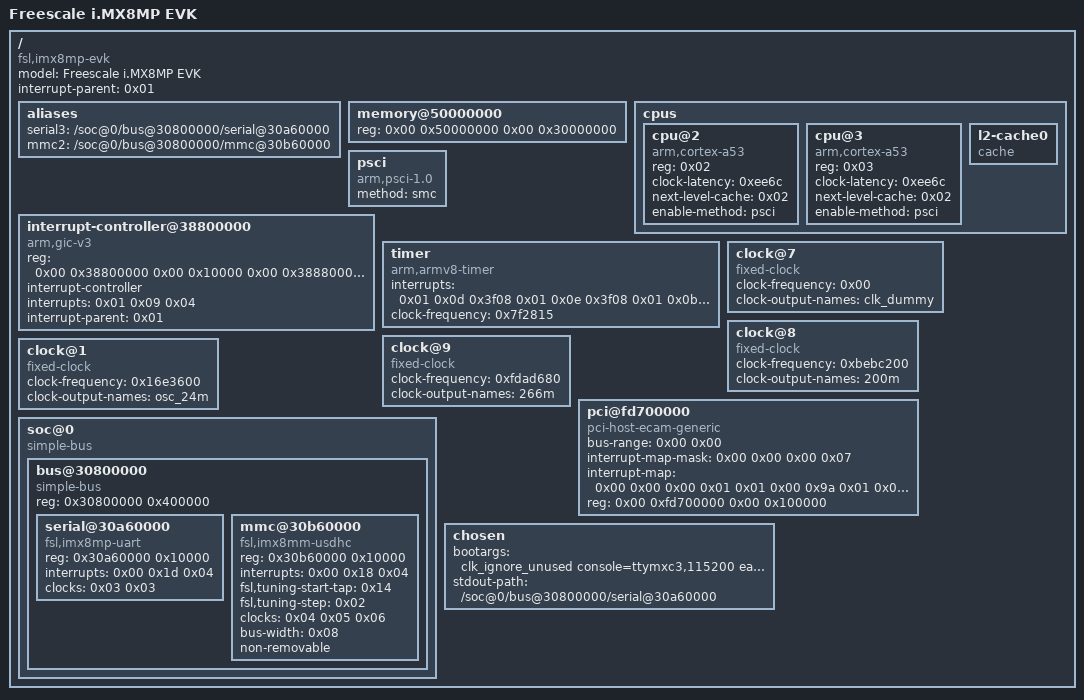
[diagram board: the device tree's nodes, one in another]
/dts-v1/;

/ {
	model = "Freescale i.MX8MP EVK";
	compatible = "fsl,imx8mp-evk\0fsl,imx8mp";
	interrupt-parent = <0x01>;
	#address-cells = <0x02>;
	#size-cells = <0x02>;

	aliases {
		serial3 = "/soc@0/bus@30800000/serial@30a60000";
		mmc2 = "/soc@0/bus@30800000/mmc@30b60000";
	};

	memory@50000000 {
		device_type = "memory";
		reg = <0x00 0x50000000 0x00 0x30000000>;
	};
	
	cpus {
		#address-cells = <0x01>;
		#size-cells = <0x00>;

		cpu@2 {
			device_type = "cpu";
			compatible = "arm,cortex-a53";
			reg = <0x02>;
			clock-latency = <0xee6c>;
			next-level-cache = <0x02>;
			enable-method = "psci";
			#cooling-cells = <0x02>;
		};

		cpu@3 {
			device_type = "cpu";
			compatible = "arm,cortex-a53";
			reg = <0x03>;
			clock-latency = <0xee6c>;
			next-level-cache = <0x02>;
			enable-method = "psci";
			#cooling-cells = <0x02>;
		};

		l2-cache0 {
			compatible = "cache";
			phandle = <0x02>;
		};
	};

	psci {
		compatible = "arm,psci-1.0";
		method = "smc";
	};

	interrupt-controller@38800000 {
		compatible = "arm,gic-v3";
		reg = <0x00 0x38800000 0x00 0x10000 0x00 0x38880000 0x00 0xc0000>;
		#interrupt-cells = <0x03>;
		interrupt-controller;
		interrupts = <0x01 0x09 0x04>;
		interrupt-parent = <0x01>;
		phandle = <0x01>;
	};

	timer {
		compatible = "arm,armv8-timer";
		interrupts = <0x01 0x0d 0x3f08 0x01 0x0e 0x3f08 0x01 0x0b 0x3f08 0x01 0x0a 0x3f08>;
		clock-frequency = <0x7f2815>;
	};

	clock@7 {
		compatible = "fixed-clock";
		#clock-cells = <0x00>;
		clock-frequency = <0x00>;
		clock-output-names = "clk_dummy";
		phandle = <0x04>;
	};

	clock@8 {
		compatible = "fixed-clock";
		#clock-cells = <0x00>;
		clock-frequency = <0xbebc200>;
		clock-output-names = "200m";
		phandle = <0x06>;
	};

	clock@9 {
		compatible = "fixed-clock";
		#clock-cells = <0x00>;
		clock-frequency = <0xfdad680>;
		clock-output-names = "266m";
		phandle = <0x05>;
	};

	clock@1 {
		compatible = "fixed-clock";
		#clock-cells = <0x00>;
		clock-frequency = <0x16e3600>;
		clock-output-names = "osc_24m";
		phandle = <0x03>;
	};

	pci@fd700000 {
		compatible = "pci-host-ecam-generic";
		device_type = "pci";
		bus-range = <0x00 0x00>;
		#address-cells = <0x03>;
		#size-cells = <0x02>;
		#interrupt-cells = <0x01>;
		interrupt-map-mask = <0x00 0x00 0x00 0x07>;
		interrupt-map = <0x00 0x00 0x00 0x01 0x01 0x00 0x9a 0x01 0x00 0x00 0x00 0x02 0x01 0x00 0x9b 0x01 0x00 0x00 0x00 0x03 0x01 0x00 0x9c 0x01 0x00 0x00 0x00 0x04 0x01 0x00 0x9d 0x01>;
		reg = <0x00 0xfd700000 0x00 0x100000>;
		ranges = <0x2000000 0x00 0x10000000 0x00 0x10000000 0x00 0x10000>;
	};

	soc@0 {
		compatible = "simple-bus";
		#address-cells = <0x01>;
		#size-cells = <0x01>;
		ranges = <0x00 0x00 0x00 0x3e000000>;

		bus@30800000 {
			compatible = "simple-bus";
			reg = <0x30800000 0x400000>;
			#address-cells = <0x01>;
			#size-cells = <0x01>;
			ranges;

			serial@30a60000 {
				compatible = "fsl,imx8mp-uart\0fsl,imx6q-uart";
				reg = <0x30a60000 0x10000>;
				interrupts = <0x00 0x1d 0x04>;
				status = "okay";
				clocks = <0x03 0x03>;
				clock-names = "ipg\0per";
			};

			mmc@30b60000 {
				compatible = "fsl,imx8mm-usdhc\0fsl,imx7d-usdhc";
				reg = <0x30b60000 0x10000>;
				interrupts = <0x00 0x18 0x04>;
				fsl,tuning-start-tap = <0x14>;
				fsl,tuning-step = <0x02>;
				status = "okay";
				clocks = <0x04 0x05 0x06>;
				clock-names = "ipg\0ahb\0per";
				bus-width = <0x08>;
				non-removable;
			};
		};
	};

	chosen {
		// bootargs = "clk_ignore_unused console=ttymxc3,115200 earlycon=ec_imx6q,0x30890000,115200 root=/dev/vda rootwait rw";
		bootargs = "clk_ignore_unused console=ttymxc3,115200 earlycon=ec_imx6q,0x30a60000,115200 root=/dev/mmcblk2p1 rootwait rw";
		stdout-path = "/soc@0/bus@30800000/serial@30a60000";
	};
};
